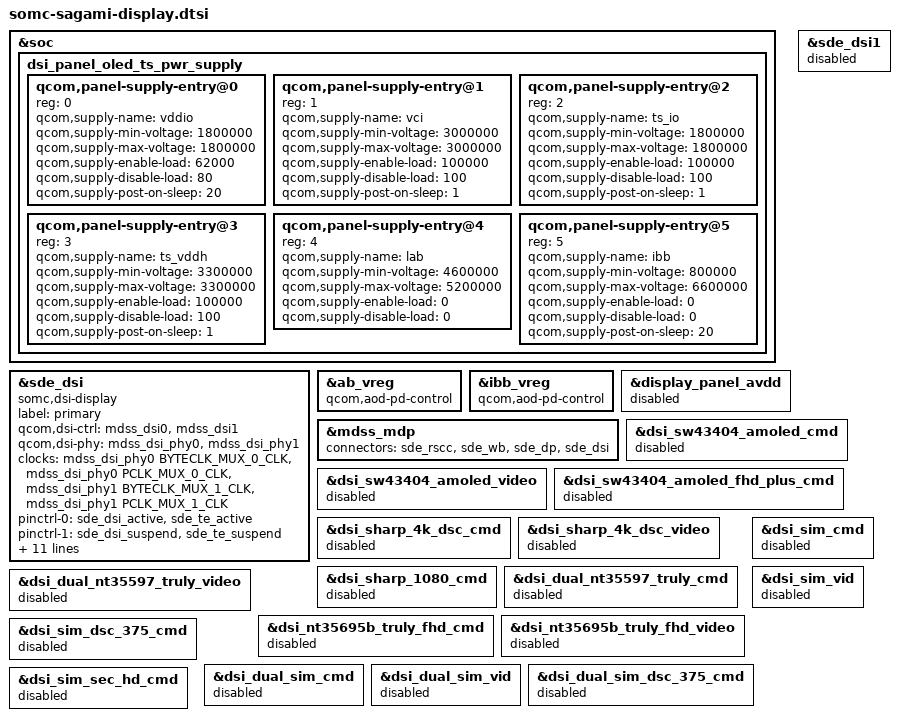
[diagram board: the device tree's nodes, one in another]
&soc {
	dsi_panel_oled_ts_pwr_supply: dsi_panel_oled_ts_pwr_supply {
		#address-cells = <1>;
		#size-cells = <0>;

		qcom,panel-supply-entry@0 {
			reg = <0>;
			qcom,supply-name = "vddio";
			qcom,supply-min-voltage = <1800000>;
			qcom,supply-max-voltage = <1800000>;
			qcom,supply-enable-load = <62000>;
			qcom,supply-disable-load = <80>;
			qcom,supply-post-on-sleep = <20>;
		};

		qcom,panel-supply-entry@1 {
			reg = <1>;
			qcom,supply-name = "vci";
			qcom,supply-min-voltage = <3000000>;
			qcom,supply-max-voltage = <3000000>;
			qcom,supply-enable-load = <100000>;
			qcom,supply-disable-load = <100>;
			qcom,supply-post-on-sleep = <1>;
		};
		qcom,panel-supply-entry@2 {
			reg = <2>;
			qcom,supply-name = "ts_io";
			qcom,supply-min-voltage = <1800000>;
			qcom,supply-max-voltage = <1800000>;
			qcom,supply-enable-load = <100000>;
			qcom,supply-disable-load = <100>;
			qcom,supply-post-on-sleep = <1>;
		};
		qcom,panel-supply-entry@3 {
			reg = <3>;
			qcom,supply-name = "ts_vddh";
			qcom,supply-min-voltage = <3300000>;
			qcom,supply-max-voltage = <3300000>;
			qcom,supply-enable-load = <100000>;
			qcom,supply-disable-load = <100>;
			qcom,supply-post-on-sleep = <1>;
		};

		qcom,panel-supply-entry@4 {
			reg = <4>;
			qcom,supply-name = "lab";
			qcom,supply-min-voltage = <4600000>;
			qcom,supply-max-voltage = <5200000>;
			qcom,supply-enable-load = <0>;
			qcom,supply-disable-load = <0>;
		};

		qcom,panel-supply-entry@5 {
			reg = <5>;
			qcom,supply-name = "ibb";
			qcom,supply-min-voltage = <800000>;
			qcom,supply-max-voltage = <6600000>;
			qcom,supply-enable-load = <0>;
			qcom,supply-disable-load = <0>;
			qcom,supply-post-on-sleep = <20>;
		};
	};
};

&sde_dsi {
	compatible = "somc,dsi-display";
	label = "primary";

	qcom,dsi-ctrl = <&mdss_dsi0 &mdss_dsi1>;
	qcom,dsi-phy = <&mdss_dsi_phy0 &mdss_dsi_phy1>;

	clocks = <&mdss_dsi_phy0 BYTECLK_MUX_0_CLK>,
		 <&mdss_dsi_phy0 PCLK_MUX_0_CLK>,
		 <&mdss_dsi_phy1 BYTECLK_MUX_1_CLK>,
		 <&mdss_dsi_phy1 PCLK_MUX_1_CLK>;
	clock-names = "mux_byte_clk0", "mux_pixel_clk0",
		      "mux_byte_clk1", "mux_pixel_clk1";

	pinctrl-names = "panel_active", "panel_suspend",
			"somc_ts_int_active", "somc_ts_int_suspend";
	pinctrl-0 = <&sde_dsi_active &sde_te_active>;
	pinctrl-1 = <&sde_dsi_suspend &sde_te_suspend>;
	pinctrl-2 = <&somc_ts_int_active>;
	pinctrl-3 = <&somc_ts_int_suspend>;

	qcom,platform-te-gpio = <&tlmm 82 0>;
	qcom,panel-te-source = <0>;

	vddio-supply = <&pm8350c_l12>;
	vci-supply = <&pm8350c_l13>;
	ts_io-supply = <&pm8350c_l2>;
	ts_vddh-supply = <&pm8350c_l3>;
	lab-supply = <&ab_vreg>;
	ibb-supply = <&ibb_vreg>;
	/delete-property/vdd-supply;
	/delete-property/avdd-supply;

	qcom,mdp = <&mdss_mdp>;
};

&ab_vreg {
	qcom,aod-pd-control;
};

&ibb_vreg {
	qcom,aod-pd-control;
};

&display_panel_avdd {
	status = "disabled";
};

&sde_dsi1 {
	status = "disabled";
};

&mdss_mdp {
	connectors = <&sde_rscc &sde_wb &sde_dp &sde_dsi>;
};

&dsi_sw43404_amoled_cmd {
	status = "disabled";
};

&dsi_sw43404_amoled_video {
	status = "disabled";
};

&dsi_sw43404_amoled_fhd_plus_cmd {
	status = "disabled";
};

&dsi_sharp_4k_dsc_cmd {
	status = "disabled";
};

&dsi_sharp_4k_dsc_video {
	status = "disabled";
};

&dsi_sharp_1080_cmd {
	status = "disabled";
};

&dsi_dual_nt35597_truly_cmd {
	status = "disabled";
};

&dsi_dual_nt35597_truly_video {
	status = "disabled";
};

&dsi_nt35695b_truly_fhd_cmd {
	status = "disabled";
};

&dsi_nt35695b_truly_fhd_video {
	status = "disabled";
};

&dsi_sim_cmd {
	status = "disabled";
};

&dsi_sim_vid {
	status = "disabled";
};

&dsi_sim_dsc_375_cmd {
	status = "disabled";
};

&dsi_dual_sim_cmd {
	status = "disabled";
};

&dsi_dual_sim_vid {
	status = "disabled";
};

&dsi_dual_sim_dsc_375_cmd {
	status = "disabled";
};

&dsi_sim_sec_hd_cmd {
	status = "disabled";
};

